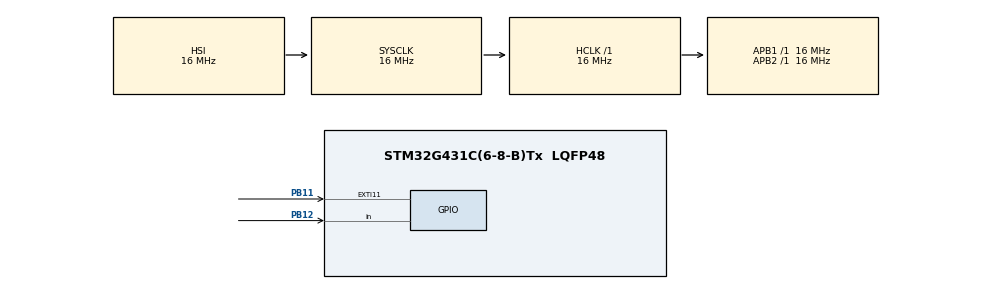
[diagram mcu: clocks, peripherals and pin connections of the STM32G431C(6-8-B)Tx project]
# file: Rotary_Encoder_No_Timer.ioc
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Mcu.Family=STM32G4
Mcu.Name=STM32G431C(6-8-B)Tx
Mcu.Package=LQFP48
NVIC.EXTI15_10_IRQn=true\:0\:0\:false\:false\:true\:true\:true\:true
NVIC.PriorityGroup=NVIC_PRIORITYGROUP_4
PB11.GPIO_PuPd=GPIO_PULLUP
PB11.Signal=GPXTI11
PB12.GPIO_PuPd=GPIO_PULLUP
PB12.Signal=GPIO_Input
ProjectManager.HeapSize=0x200
ProjectManager.StackSize=0x400
ProjectManager.TargetToolchain=STM32CubeIDE
RCC.AHBFreq_Value=16000000
RCC.APB1Freq_Value=16000000
RCC.APB1TimFreq_Value=16000000
RCC.APB2Freq_Value=16000000
RCC.APB2TimFreq_Value=16000000
RCC.CortexFreq_Value=16000000
RCC.EXTERNAL_CLOCK_VALUE=12288000
RCC.HCLKFreq_Value=16000000
RCC.HSE_VALUE=8000000
RCC.HSI48_VALUE=48000000
RCC.HSI_VALUE=16000000
RCC.LSE_VALUE=32768
RCC.SYSCLKFreq_VALUE=16000000
RCC.USBFreq_Value=64000000
RCC.VCOOutputFreq_Value=128000000
board=custom

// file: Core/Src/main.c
/* USER CODE BEGIN Header */
/**
  ******************************************************************************
  * @file           : main.c
  * @brief          : Main program body
  ******************************************************************************
  * @attention
  *
  * Copyright (c) 2025 STMicroelectronics.
  * All rights reserved.
  *
  * This software is licensed under terms that can be found in the LICENSE file
  * in the root directory of this software component.
  * If no LICENSE file comes with this software, it is provided AS-IS.
  *
  ******************************************************************************
  */
/* USER CODE END Header */
#include "main.h"

/* USER CODE BEGIN Includes */
#include <stdio.h>
#include <stdlib.h>
#include <stdint.h>
/* USER CODE END Includes */

/* USER CODE BEGIN PV */
volatile int encoder_count = 0;
/* USER CODE END PV */

void SystemClock_Config(void);
static void MX_GPIO_Init(void);

int main(void)
{

  /* MCU Configuration--------------------------------------------------------*/

  /* Reset of all peripherals, Initializes the Flash interface and the Systick. */
  HAL_Init();

  /* Configure the system clock */
  SystemClock_Config();

  /* Initialize all configured peripherals */
  MX_GPIO_Init();

  /* Infinite loop */
  while (1)
  {

  }
}

void SystemClock_Config(void)
{
  RCC_OscInitTypeDef RCC_OscInitStruct = {0};
  RCC_ClkInitTypeDef RCC_ClkInitStruct = {0};

  /** Configure the main internal regulator output voltage
  */
  HAL_PWREx_ControlVoltageScaling(PWR_REGULATOR_VOLTAGE_SCALE1);

  /** Initializes the RCC Oscillators according to the specified parameters
  * in the RCC_OscInitTypeDef structure.
  */
  RCC_OscInitStruct.OscillatorType = RCC_OSCILLATORTYPE_HSI;
  RCC_OscInitStruct.HSIState = RCC_HSI_ON;
  RCC_OscInitStruct.HSICalibrationValue = RCC_HSICALIBRATION_DEFAULT;
  RCC_OscInitStruct.PLL.PLLState = RCC_PLL_NONE;
  if (HAL_RCC_OscConfig(&RCC_OscInitStruct) != HAL_OK)
  {
    Error_Handler();
  }

  /** Initializes the CPU, AHB and APB buses clocks
  */
  RCC_ClkInitStruct.ClockType = RCC_CLOCKTYPE_HCLK|RCC_CLOCKTYPE_SYSCLK
                              |RCC_CLOCKTYPE_PCLK1|RCC_CLOCKTYPE_PCLK2;
  RCC_ClkInitStruct.SYSCLKSource = RCC_SYSCLKSOURCE_HSI;
  RCC_ClkInitStruct.AHBCLKDivider = RCC_SYSCLK_DIV1;
  RCC_ClkInitStruct.APB1CLKDivider = RCC_HCLK_DIV1;
  RCC_ClkInitStruct.APB2CLKDivider = RCC_HCLK_DIV1;

  if (HAL_RCC_ClockConfig(&RCC_ClkInitStruct, FLASH_LATENCY_0) != HAL_OK)
  {
    Error_Handler();
  }
}

static void MX_GPIO_Init(void)
{
  GPIO_InitTypeDef GPIO_InitStruct = {0};

  /* GPIO Ports Clock Enable */
  __HAL_RCC_GPIOB_CLK_ENABLE();

  /*Configure GPIO pin : PB11 */
  GPIO_InitStruct.Pin = GPIO_PIN_11;
  GPIO_InitStruct.Mode = GPIO_MODE_IT_RISING;
  GPIO_InitStruct.Pull = GPIO_PULLUP;
  HAL_GPIO_Init(GPIOB, &GPIO_InitStruct);

  /*Configure GPIO pin : PB12 */
  GPIO_InitStruct.Pin = GPIO_PIN_12;
  GPIO_InitStruct.Mode = GPIO_MODE_INPUT;
  GPIO_InitStruct.Pull = GPIO_PULLUP;
  HAL_GPIO_Init(GPIOB, &GPIO_InitStruct);

  /* EXTI interrupt init*/
  HAL_NVIC_SetPriority(EXTI15_10_IRQn, 0, 0);
  HAL_NVIC_EnableIRQ(EXTI15_10_IRQn);

}

/* USER CODE BEGIN 4 */
void HAL_GPIO_EXTI_Callback(uint16_t GPIO_Pin) {
	// check pin
	if (GPIO_Pin == GPIO_PIN_11) {
		if (HAL_GPIO_ReadPin(GPIOB, GPIO_PIN_12) == GPIO_PIN_RESET) {
			// printf("Going counter clockwise\n");
			// fflush(stdout);
			if (encoder_count == 359) {
				encoder_count = 0;
				printf("1 rev\n");
				fflush(stdout);
			} else {
				encoder_count++;
			}
			// since 360 resolution, one count maps to 1 degree:
			// printf("Encoder position: %d degrees\n", encoder_count);
		} else {
			// printf("Going clockwise\n");
			// fflush(stdout);
			if (encoder_count == 0) {
				encoder_count = 359;
			} else {
				encoder_count--;
			}
			// printf("Encoder position: %d degrees\n", encoder_count);
		}
	}
}

/* USER CODE END 4 */

void Error_Handler(void)
{
  __disable_irq();
  while (1)
  {
  }
}
